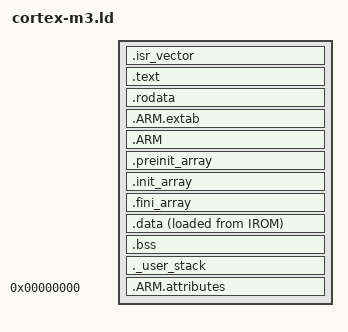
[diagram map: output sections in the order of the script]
ENTRY(lmcu_reset_handler);

_stack_size = 0x400;
__stack = ALIGN(ORIGIN(IRAM) + LENGTH(IRAM) - 8, 8);
PROVIDE( _estack = __stack );

SECTIONS
{
  /* Interrupt vector table */
  .isr_vector :
  {
    . = ALIGN(4);
    KEEP(*(.isr_vector))
    . = ALIGN(4);
  } > IROM

  /* The program code and other data */
  .text :
  {
    . = ALIGN(4);
    *(.text)      /* .text sections (code) */
    *(.text*)     /* .text* sections (code) */
    *(.glue_7)    /* glue arm to thumb code */
    *(.glue_7t)   /* glue thumb to arm code */
    *(.eh_frame)

    KEEP (*(.init))
    KEEP (*(.fini))

    . = ALIGN(4);
    _etext = .; /* define a global symbols at end of code */
    _exit = .;
  } > IROM

  /* Constant data */
  .rodata :
  {
    . = ALIGN(4);
    *(.rodata)
    *(.rodata*)
    . = ALIGN(4);
  } > IROM

  .ARM.extab :
  {
    *(.ARM.extab* .gnu.linkonce.armextab.*)
  } > IROM

  .ARM :
  {
    __exidx_start = .;
    *(.ARM.exidx*)
    __exidx_end = .;
  } > IROM

  .preinit_array :
  {
    PROVIDE_HIDDEN (__preinit_array_start = .);
    KEEP (*(.preinit_array*))
    PROVIDE_HIDDEN (__preinit_array_end = .);
  } > IROM

  .init_array :
  {
    PROVIDE_HIDDEN (__init_array_start = .);
    KEEP (*(SORT(.init_array.*)))
    KEEP (*(.init_array*))
    PROVIDE_HIDDEN (__init_array_end = .);
  } > IROM

  .fini_array :
  {
    PROVIDE_HIDDEN (__fini_array_start = .);
    KEEP (*(.fini_array*))
    KEEP (*(SORT(.fini_array.*)))
    PROVIDE_HIDDEN (__fini_array_end = .);
  } > IROM

  /* used by the startup to initialize data */
  _sidata = LOADADDR(.data);

  /* Initialized data sections goes into RAM, load LMA copy after code */
  .data :
  {
    . = ALIGN(4);
    _sdata = .; /* create a global symbol at data start */
    *(vtable)
    *(.data)
    *(.data*)

    . = ALIGN(4);
    _edata = .; /* define a global symbol at data end */
  } > IRAM AT > IROM

  /* Uninitialized data section */
  . = ALIGN(4);
  .bss :
  {
    /* This is used by the startup in order to initialize the .bss secion */
    _sbss = .;         /* define a global symbol at bss start */
    __bss_start__ = _sbss;
    *(.bss)
    *(.bss*)
    *(COMMON)

    . = ALIGN(4);
    _ebss = .;         /* define a global symbol at bss end */
    __bss_end__ = _ebss;
  } > IRAM

  /* _user_stack section, used to check that there is enough RAM left */
  ._user_stack :
  {
    . = ALIGN(4);
    PROVIDE ( end = . );
    PROVIDE ( _end = . );
    . = . + _stack_size;
    . = ALIGN(4);
  } > IRAM

  /* Remove information from the standard libraries */
  /DISCARD/ :
  {
    libc.a ( * )
    libm.a ( * )
    libgcc.a ( * )
    libstdc++.a ( * )
  }

  .ARM.attributes 0 :
  {
    *(.ARM.attributes)
  }
}
